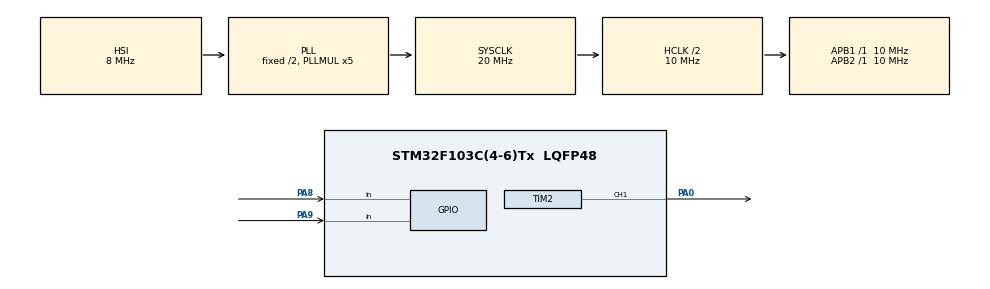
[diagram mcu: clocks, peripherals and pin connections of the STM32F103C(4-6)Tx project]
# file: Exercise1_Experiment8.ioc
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Mcu.Family=STM32F1
Mcu.Name=STM32F103C(4-6)Tx
Mcu.Package=LQFP48
NVIC.PriorityGroup=NVIC_PRIORITYGROUP_4
PA0-WKUP.Signal=S_TIM2_CH1_ETR
PA8.GPIO_PuPd=GPIO_PULLUP
PA8.Signal=GPIO_Input
PA9.GPIO_PuPd=GPIO_PULLUP
PA9.Signal=GPIO_Input
ProjectManager.HeapSize=0x200
ProjectManager.StackSize=0x400
ProjectManager.TargetToolchain=STM32CubeIDE
RCC.AHBCLKDivider=RCC_SYSCLK_DIV2
RCC.AHBFreq_Value=10000000
RCC.APB1Freq_Value=10000000
RCC.APB1TimFreq_Value=10000000
RCC.APB2Freq_Value=10000000
RCC.APB2TimFreq_Value=10000000
RCC.HCLKFreq_Value=10000000
RCC.PLLMUL=RCC_PLL_MUL5
RCC.SYSCLKFreq_VALUE=20000000
RCC.SYSCLKSource=RCC_SYSCLKSOURCE_PLLCLK
RCC.USBFreq_Value=20000000
SH.S_TIM2_CH1_ETR.0=TIM2_CH1,PWM Generation1 CH1
TIM2.Channel-PWM\ Generation1\ CH1=TIM_CHANNEL_1
TIM2.Period=100-1
TIM2.Prescaler=10-1
VP_TIM2_VS_ClockSourceINT.Mode=Internal
board=custom

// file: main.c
/* USER CODE BEGIN Header */
/**
  ******************************************************************************
  * @file           : main.c
  * @brief          : Main program body
  ******************************************************************************
  * @attention
  *
  * Copyright (c) 2023 STMicroelectronics.
  * All rights reserved.
  *
  * This software is licensed under terms that can be found in the LICENSE file
  * in the root directory of this software component.
  * If no LICENSE file comes with this software, it is provided AS-IS.
  *
  ******************************************************************************
  */
/* USER CODE END Header */
#include "main.h"

TIM_HandleTypeDef htim2;

void SystemClock_Config(void);
static void MX_GPIO_Init(void);
static void MX_TIM2_Init(void);

int main(void)
{

  /* MCU Configuration--------------------------------------------------------*/

  /* Reset of all peripherals, Initializes the Flash interface and the Systick. */
  HAL_Init();

  /* Configure the system clock */
  SystemClock_Config();

  /* Initialize all configured peripherals */
  MX_GPIO_Init();
  MX_TIM2_Init();
  /* USER CODE BEGIN 2 */
    uint8_t pwm_base=6;
	//uint8_t up_down_flag=1;
	HAL_TIM_PWM_Start(&htim2, TIM_CHANNEL_1);
  /* USER CODE END 2 */

  /* Infinite loop */
  while (1)
  {

    /* USER CODE BEGIN 3 */
	  __HAL_TIM_SET_COMPARE(&htim2,TIM_CHANNEL_1,pwm_base);
	 	  if(pwm_base>=99){
	 		  //up_down_flag=0;
	 		  pwm_base=0;
	 	  }
	 	  else if(pwm_base<=1){
	 		   pwm_base=100;
	 		  //up_down_flag=1;
	 	  }
	 	  if(HAL_GPIO_ReadPin(GPIOA, GPIO_PIN_9)==0){
	 		  pwm_base+=2;
	 	  }
	 	 //HAL_Delay(50);
	 	 if(HAL_GPIO_ReadPin(GPIOA, GPIO_PIN_8)==0){
	 		 		  pwm_base-=2;
	 		 	  }

	 	  //pwm_base=up_down_flag ? (pwm_base+2):(pwm_base-6);
	 	  HAL_Delay(50);
  }
  /* USER CODE END 3 */
}

void SystemClock_Config(void)
{
  RCC_OscInitTypeDef RCC_OscInitStruct = {0};
  RCC_ClkInitTypeDef RCC_ClkInitStruct = {0};

  /** Initializes the RCC Oscillators according to the specified parameters
  * in the RCC_OscInitTypeDef structure.
  */
  RCC_OscInitStruct.OscillatorType = RCC_OSCILLATORTYPE_HSI;
  RCC_OscInitStruct.HSIState = RCC_HSI_ON;
  RCC_OscInitStruct.HSICalibrationValue = RCC_HSICALIBRATION_DEFAULT;
  RCC_OscInitStruct.PLL.PLLState = RCC_PLL_ON;
  RCC_OscInitStruct.PLL.PLLSource = RCC_PLLSOURCE_HSI_DIV2;
  RCC_OscInitStruct.PLL.PLLMUL = RCC_PLL_MUL5;
  if (HAL_RCC_OscConfig(&RCC_OscInitStruct) != HAL_OK)
  {
    Error_Handler();
  }

  /** Initializes the CPU, AHB and APB buses clocks
  */
  RCC_ClkInitStruct.ClockType = RCC_CLOCKTYPE_HCLK|RCC_CLOCKTYPE_SYSCLK
                              |RCC_CLOCKTYPE_PCLK1|RCC_CLOCKTYPE_PCLK2;
  RCC_ClkInitStruct.SYSCLKSource = RCC_SYSCLKSOURCE_PLLCLK;
  RCC_ClkInitStruct.AHBCLKDivider = RCC_SYSCLK_DIV2;
  RCC_ClkInitStruct.APB1CLKDivider = RCC_HCLK_DIV1;
  RCC_ClkInitStruct.APB2CLKDivider = RCC_HCLK_DIV1;

  if (HAL_RCC_ClockConfig(&RCC_ClkInitStruct, FLASH_LATENCY_0) != HAL_OK)
  {
    Error_Handler();
  }
}

static void MX_TIM2_Init(void)
{

  TIM_ClockConfigTypeDef sClockSourceConfig = {0};
  TIM_MasterConfigTypeDef sMasterConfig = {0};
  TIM_OC_InitTypeDef sConfigOC = {0};

  htim2.Instance = TIM2;
  htim2.Init.Prescaler = 10-1;
  htim2.Init.CounterMode = TIM_COUNTERMODE_UP;
  htim2.Init.Period = 100-1;
  htim2.Init.ClockDivision = TIM_CLOCKDIVISION_DIV1;
  htim2.Init.AutoReloadPreload = TIM_AUTORELOAD_PRELOAD_DISABLE;
  if (HAL_TIM_Base_Init(&htim2) != HAL_OK)
  {
    Error_Handler();
  }
  sClockSourceConfig.ClockSource = TIM_CLOCKSOURCE_INTERNAL;
  if (HAL_TIM_ConfigClockSource(&htim2, &sClockSourceConfig) != HAL_OK)
  {
    Error_Handler();
  }
  if (HAL_TIM_PWM_Init(&htim2) != HAL_OK)
  {
    Error_Handler();
  }
  sMasterConfig.MasterOutputTrigger = TIM_TRGO_RESET;
  sMasterConfig.MasterSlaveMode = TIM_MASTERSLAVEMODE_DISABLE;
  if (HAL_TIMEx_MasterConfigSynchronization(&htim2, &sMasterConfig) != HAL_OK)
  {
    Error_Handler();
  }
  sConfigOC.OCMode = TIM_OCMODE_PWM1;
  sConfigOC.Pulse = 0;
  sConfigOC.OCPolarity = TIM_OCPOLARITY_HIGH;
  sConfigOC.OCFastMode = TIM_OCFAST_DISABLE;
  if (HAL_TIM_PWM_ConfigChannel(&htim2, &sConfigOC, TIM_CHANNEL_1) != HAL_OK)
  {
    Error_Handler();
  }
  HAL_TIM_MspPostInit(&htim2);

}

static void MX_GPIO_Init(void)
{
  GPIO_InitTypeDef GPIO_InitStruct = {0};

  /* GPIO Ports Clock Enable */
  __HAL_RCC_GPIOA_CLK_ENABLE();

  /*Configure GPIO pins : PA8 PA9 */
  GPIO_InitStruct.Pin = GPIO_PIN_8|GPIO_PIN_9;
  GPIO_InitStruct.Mode = GPIO_MODE_INPUT;
  GPIO_InitStruct.Pull = GPIO_PULLUP;
  HAL_GPIO_Init(GPIOA, &GPIO_InitStruct);

}

void Error_Handler(void)
{
  __disable_irq();
  while (1)
  {
  }
}
